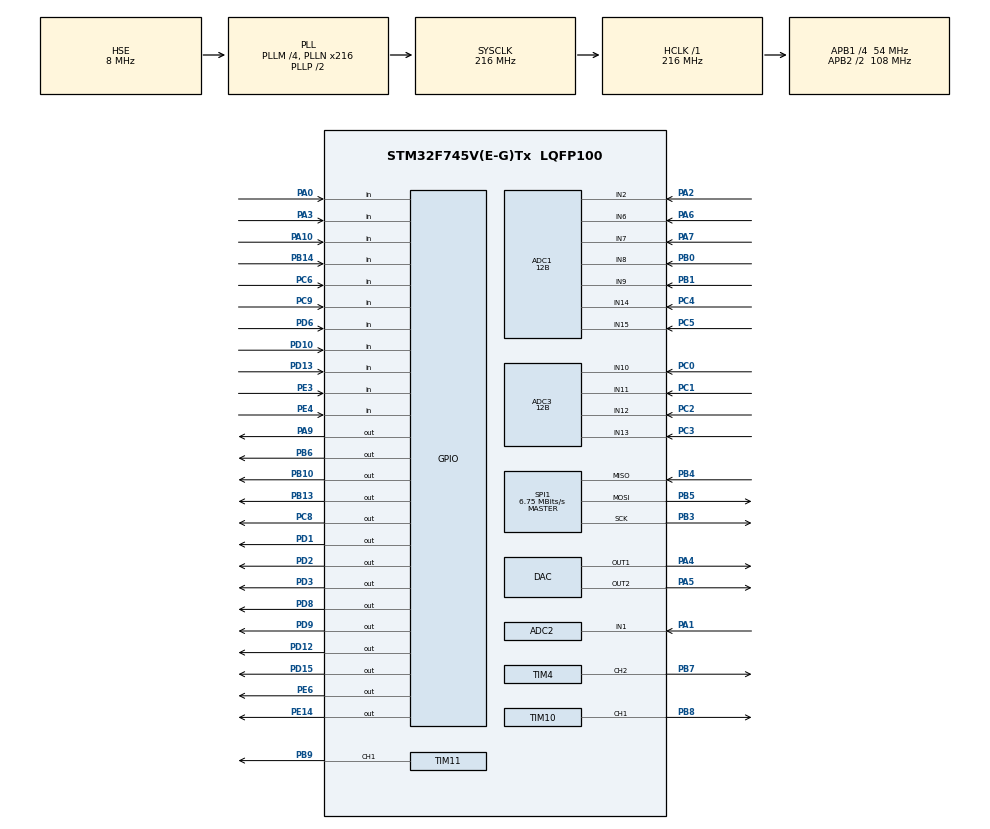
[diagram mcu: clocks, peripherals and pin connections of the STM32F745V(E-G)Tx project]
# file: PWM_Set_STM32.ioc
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ADC1.Channel-0\#ChannelRegularConversion=ADC_CHANNEL_2
ADC1.Channel-1\#ChannelRegularConversion=ADC_CHANNEL_6
ADC1.Channel-2\#ChannelRegularConversion=ADC_CHANNEL_7
ADC1.Channel-3\#ChannelRegularConversion=ADC_CHANNEL_14
ADC1.Channel-4\#ChannelRegularConversion=ADC_CHANNEL_15
ADC1.Channel-5\#ChannelRegularConversion=ADC_CHANNEL_8
ADC1.Channel-6\#ChannelRegularConversion=ADC_CHANNEL_9
ADC1.ClockPrescaler=ADC_CLOCK_SYNC_PCLK_DIV4
ADC1.ContinuousConvMode=ENABLE
ADC1.DMAContinuousRequests=ENABLE
ADC1.DataAlign=ADC_DATAALIGN_RIGHT
ADC1.DiscontinuousConvMode=DISABLE
ADC1.EOCSelection=ADC_EOC_SEQ_CONV
ADC1.EnableAnalogWatchDog=false
ADC1.ExternalTrigConv=ADC_SOFTWARE_START
ADC1.ExternalTrigConvEdge=ADC_EXTERNALTRIGCONVEDGE_NONE
ADC1.InjNumberOfConversion=0
ADC1.NbrOfConversion=7
ADC1.NbrOfConversionFlag=1
ADC1.Rank-0\#ChannelRegularConversion=1
ADC1.Rank-1\#ChannelRegularConversion=2
ADC1.Rank-2\#ChannelRegularConversion=3
ADC1.Rank-3\#ChannelRegularConversion=4
ADC1.Rank-4\#ChannelRegularConversion=5
ADC1.Rank-5\#ChannelRegularConversion=6
ADC1.Rank-6\#ChannelRegularConversion=7
ADC1.Resolution=ADC_RESOLUTION_12B
ADC1.SamplingTime-0\#ChannelRegularConversion=ADC_SAMPLETIME_3CYCLES
ADC1.SamplingTime-1\#ChannelRegularConversion=ADC_SAMPLETIME_3CYCLES
ADC1.SamplingTime-2\#ChannelRegularConversion=ADC_SAMPLETIME_3CYCLES
ADC1.SamplingTime-3\#ChannelRegularConversion=ADC_SAMPLETIME_3CYCLES
ADC1.SamplingTime-4\#ChannelRegularConversion=ADC_SAMPLETIME_3CYCLES
ADC1.SamplingTime-5\#ChannelRegularConversion=ADC_SAMPLETIME_3CYCLES
ADC1.SamplingTime-6\#ChannelRegularConversion=ADC_SAMPLETIME_3CYCLES
ADC1.ScanConvMode=ENABLE
ADC1.master=1
ADC2.Channel-0\#ChannelRegularConversion=ADC_CHANNEL_1
ADC2.ClockPrescaler=ADC_CLOCK_SYNC_PCLK_DIV4
ADC2.DMAContinuousRequests=ENABLE
ADC2.EOCSelection=ADC_EOC_SEQ_CONV
ADC2.ExternalTrigConv=ADC_EXTERNALTRIGCONV_T8_TRGO
ADC2.NbrOfConversionFlag=1
ADC2.Rank-0\#ChannelRegularConversion=1
ADC2.SamplingTime-0\#ChannelRegularConversion=ADC_SAMPLETIME_3CYCLES
ADC2.ScanConvMode=ENABLE
ADC3.Channel-0\#ChannelRegularConversion=ADC_CHANNEL_10
ADC3.Channel-1\#ChannelRegularConversion=ADC_CHANNEL_11
ADC3.Channel-2\#ChannelRegularConversion=ADC_CHANNEL_12
ADC3.Channel-3\#ChannelRegularConversion=ADC_CHANNEL_13
ADC3.ClockPrescaler=ADC_CLOCK_SYNC_PCLK_DIV4
ADC3.ContinuousConvMode=DISABLE
ADC3.DMAContinuousRequests=ENABLE
ADC3.DataAlign=ADC_DATAALIGN_RIGHT
ADC3.DiscontinuousConvMode=DISABLE
ADC3.EOCSelection=ADC_EOC_SEQ_CONV
ADC3.EnableAnalogWatchDog=false
ADC3.ExternalTrigConv=ADC_EXTERNALTRIGCONV_T6_TRGO
ADC3.ExternalTrigConvEdge=ADC_EXTERNALTRIGCONVEDGE_RISING
ADC3.InjNumberOfConversion=0
ADC3.NbrOfConversion=4
ADC3.NbrOfConversionFlag=1
ADC3.Rank-0\#ChannelRegularConversion=1
ADC3.Rank-1\#ChannelRegularConversion=2
ADC3.Rank-2\#ChannelRegularConversion=3
ADC3.Rank-3\#ChannelRegularConversion=4
ADC3.Resolution=ADC_RESOLUTION_12B
ADC3.SamplingTime-0\#ChannelRegularConversion=ADC_SAMPLETIME_3CYCLES
ADC3.SamplingTime-1\#ChannelRegularConversion=ADC_SAMPLETIME_3CYCLES
ADC3.SamplingTime-2\#ChannelRegularConversion=ADC_SAMPLETIME_3CYCLES
ADC3.SamplingTime-3\#ChannelRegularConversion=ADC_SAMPLETIME_3CYCLES
ADC3.ScanConvMode=ENABLE
Dma.ADC1.3.Direction=DMA_PERIPH_TO_MEMORY
Dma.ADC1.3.FIFOMode=DMA_FIFOMODE_DISABLE
Dma.ADC1.3.Instance=DMA2_Stream4
Dma.ADC1.3.MemDataAlignment=DMA_MDATAALIGN_HALFWORD
Dma.ADC1.3.MemInc=DMA_MINC_ENABLE
Dma.ADC1.3.Mode=DMA_CIRCULAR
Dma.ADC1.3.PeriphDataAlignment=DMA_PDATAALIGN_HALFWORD
Dma.ADC1.3.PeriphInc=DMA_PINC_DISABLE
Dma.ADC1.3.Priority=DMA_PRIORITY_LOW
Dma.ADC2.0.Direction=DMA_PERIPH_TO_MEMORY
Dma.ADC2.0.FIFOMode=DMA_FIFOMODE_DISABLE
Dma.ADC2.0.Instance=DMA2_Stream2
Dma.ADC2.0.MemDataAlignment=DMA_MDATAALIGN_HALFWORD
Dma.ADC2.0.MemInc=DMA_MINC_ENABLE
Dma.ADC2.0.Mode=DMA_NORMAL
Dma.ADC2.0.PeriphDataAlignment=DMA_PDATAALIGN_HALFWORD
Dma.ADC2.0.PeriphInc=DMA_PINC_DISABLE
Dma.ADC2.0.Priority=DMA_PRIORITY_LOW
Dma.ADC3.4.Direction=DMA_PERIPH_TO_MEMORY
Dma.ADC3.4.FIFOMode=DMA_FIFOMODE_DISABLE
Dma.ADC3.4.Instance=DMA2_Stream1
Dma.ADC3.4.MemDataAlignment=DMA_MDATAALIGN_HALFWORD
Dma.ADC3.4.MemInc=DMA_MINC_ENABLE
Dma.ADC3.4.Mode=DMA_NORMAL
Dma.ADC3.4.PeriphDataAlignment=DMA_PDATAALIGN_HALFWORD
Dma.ADC3.4.PeriphInc=DMA_PINC_DISABLE
Dma.ADC3.4.Priority=DMA_PRIORITY_LOW
Dma.Request0=ADC2
Dma.Request1=SPI1_RX
Dma.Request2=SPI1_TX
Dma.Request3=ADC1
Dma.Request4=ADC3
Dma.SPI1_RX.1.Direction=DMA_PERIPH_TO_MEMORY
Dma.SPI1_RX.1.FIFOMode=DMA_FIFOMODE_DISABLE
Dma.SPI1_RX.1.Instance=DMA2_Stream0
Dma.SPI1_RX.1.MemDataAlignment=DMA_MDATAALIGN_BYTE
Dma.SPI1_RX.1.MemInc=DMA_MINC_ENABLE
Dma.SPI1_RX.1.Mode=DMA_NORMAL
Dma.SPI1_RX.1.PeriphDataAlignment=DMA_PDATAALIGN_BYTE
Dma.SPI1_RX.1.PeriphInc=DMA_PINC_DISABLE
Dma.SPI1_RX.1.Priority=DMA_PRIORITY_LOW
Dma.SPI1_TX.2.Direction=DMA_MEMORY_TO_PERIPH
Dma.SPI1_TX.2.FIFOMode=DMA_FIFOMODE_DISABLE
Dma.SPI1_TX.2.Instance=DMA2_Stream3
Dma.SPI1_TX.2.MemDataAlignment=DMA_MDATAALIGN_BYTE
Dma.SPI1_TX.2.MemInc=DMA_MINC_ENABLE
Dma.SPI1_TX.2.Mode=DMA_NORMAL
Dma.SPI1_TX.2.PeriphDataAlignment=DMA_PDATAALIGN_BYTE
Dma.SPI1_TX.2.PeriphInc=DMA_PINC_DISABLE
Dma.SPI1_TX.2.Priority=DMA_PRIORITY_LOW
FREERTOS.Tasks01=defaultTask,0,128,StartDefaultTask,Default,NULL,Dynamic,NULL,NULL;statusTask,-3,128,StartStatusTask,Default,NULL,Dynamic,NULL,NULL
Mcu.Family=STM32F7
Mcu.Name=STM32F745V(E-G)Tx
Mcu.Package=LQFP100
NVIC.DMA2_Stream0_IRQn=true\:5\:0\:false\:false\:true\:true\:true
NVIC.DMA2_Stream1_IRQn=true\:5\:0\:false\:false\:true\:true\:true
NVIC.DMA2_Stream2_IRQn=true\:5\:0\:false\:false\:true\:true\:true
NVIC.DMA2_Stream3_IRQn=true\:5\:0\:false\:false\:true\:true\:true
NVIC.DMA2_Stream4_IRQn=true\:5\:0\:false\:false\:true\:true\:true
NVIC.PriorityGroup=NVIC_PRIORITYGROUP_4
NVIC.TIM2_IRQn=true\:0\:0\:false\:false\:true\:false\:true
NVIC.TimeBase=TIM2_IRQn
NVIC.TimeBaseIP=TIM2
PA0/WKUP.Signal=GPIO_Input
PA1.Signal=ADCx_IN1
PA10.Signal=GPIO_Input
PA13.Mode=Serial_Wire
PA13.Signal=SYS_JTMS-SWDIO
PA14.Mode=Serial_Wire
PA14.Signal=SYS_JTCK-SWCLK
PA2.Signal=ADCx_IN2
PA3.Signal=GPIO_Input
PA4.Signal=COMP_DAC1_group
PA5.Signal=COMP_DAC2_group
PA6.Signal=ADCx_IN6
PA7.Signal=ADCx_IN7
PA9.Signal=GPIO_Output
PB0.Signal=ADCx_IN8
PB1.Signal=ADCx_IN9
PB10.Signal=GPIO_Output
PB13.Signal=GPIO_Output
PB14.Signal=GPIO_Input
PB3.Mode=Full_Duplex_Master
PB3.Signal=SPI1_SCK
PB4.Mode=Full_Duplex_Master
PB4.Signal=SPI1_MISO
PB5.Mode=Full_Duplex_Master
PB5.Signal=SPI1_MOSI
PB6.Signal=GPIO_Output
PB7.Signal=S_TIM4_CH2
PB8.Signal=S_TIM10_CH1
PB9.Signal=S_TIM11_CH1
PC0.Signal=ADCx_IN10
PC1.Signal=ADCx_IN11
PC14/OSC32_IN.Mode=LSE-External-Oscillator
PC14/OSC32_IN.Signal=RCC_OSC32_IN
PC15/OSC32_OUT.Mode=LSE-External-Oscillator
PC15/OSC32_OUT.Signal=RCC_OSC32_OUT
PC2.Signal=ADCx_IN12
PC3.Signal=ADCx_IN13
PC4.Signal=ADCx_IN14
PC5.Signal=ADCx_IN15
PC6.Signal=GPIO_Input
PC8.Signal=GPIO_Output
PC9.Signal=GPIO_Input
PD1.Signal=GPIO_Output
PD10.Signal=GPIO_Input
PD12.Signal=GPIO_Output
PD13.Signal=GPIO_Input
PD15.Signal=GPIO_Output
PD2.Signal=GPIO_Output
PD3.Signal=GPIO_Output
PD6.Signal=GPIO_Input
PD8.Signal=GPIO_Output
PD9.Signal=GPIO_Output
PE14.Signal=GPIO_Output
PE3.Signal=GPIO_Input
PE4.Signal=GPIO_Input
PE6.Signal=GPIO_Output
PH0/OSC_IN.Mode=HSE-External-Oscillator
PH0/OSC_IN.Signal=RCC_OSC_IN
PH1/OSC_OUT.Mode=HSE-External-Oscillator
PH1/OSC_OUT.Signal=RCC_OSC_OUT
ProjectManager.HeapSize=0x200
ProjectManager.StackSize=0x400
ProjectManager.TargetToolchain=MDK-ARM V5
RCC.AHBFreq_Value=216000000
RCC.APB1CLKDivider=RCC_HCLK_DIV4
RCC.APB1Freq_Value=54000000
RCC.APB1TimFreq_Value=108000000
RCC.APB2CLKDivider=RCC_HCLK_DIV2
RCC.APB2Freq_Value=108000000
RCC.APB2TimFreq_Value=216000000
RCC.CortexFreq_Value=216000000
RCC.HCLKFreq_Value=216000000
RCC.HSE_VALUE=8000000
RCC.HSI_VALUE=16000000
RCC.PLLM=4
RCC.PLLN=216
RCC.PLLSourceVirtual=RCC_PLLSOURCE_HSE
RCC.SYSCLKFreq_VALUE=216000000
RCC.SYSCLKSource=RCC_SYSCLKSOURCE_PLLCLK
RCC.USBFreq_Value=216000000
RCC.VCOOutputFreq_Value=432000000
SH.ADCx_IN1.0=ADC2_IN1,IN1
SH.ADCx_IN10.0=ADC3_IN10,IN10
SH.ADCx_IN11.0=ADC3_IN11,IN11
SH.ADCx_IN12.0=ADC3_IN12,IN12
SH.ADCx_IN13.0=ADC3_IN13,IN13
SH.ADCx_IN14.0=ADC1_IN14,IN14
SH.ADCx_IN15.0=ADC1_IN15,IN15
SH.ADCx_IN2.0=ADC1_IN2,IN2
SH.ADCx_IN6.0=ADC1_IN6,IN6
SH.ADCx_IN7.0=ADC1_IN7,IN7
SH.ADCx_IN8.0=ADC1_IN8,IN8
SH.ADCx_IN9.0=ADC1_IN9,IN9
SH.COMP_DAC1_group.0=DAC_OUT1,DAC_OUT1
SH.COMP_DAC2_group.0=DAC_OUT2,DAC_OUT2
SH.S_TIM10_CH1.0=TIM10_CH1,PWM Generation1 CH1
SH.S_TIM11_CH1.0=TIM11_CH1,PWM Generation1 CH1
SH.S_TIM4_CH2.0=TIM4_CH2,PWM Generation2 CH2
SPI1.BaudRatePrescaler=SPI_BAUDRATEPRESCALER_16
SPI1.CalculateBaudRate=6.75 MBits/s
SPI1.DataSize=SPI_DATASIZE_8BIT
SPI1.Direction=SPI_DIRECTION_2LINES
SPI1.Mode=SPI_MODE_MASTER
SPI1.NSSPMode=SPI_NSS_PULSE_DISABLE
SPI1.VirtualType=VM_MASTER
TIM10.Channel=TIM_CHANNEL_1
TIM10.Period=1024
TIM11.Channel=TIM_CHANNEL_1
TIM11.Period=1024
TIM4.Channel-PWM\ Generation2\ CH2=TIM_CHANNEL_2
TIM4.Period=1024
TIM6.Period=216
TIM6.TIM_MasterOutputTrigger=TIM_TRGO_UPDATE
TIM8.Period=216
TIM8.TIM_MasterOutputTrigger=TIM_TRGO_UPDATE
TIM8.TIM_MasterOutputTrigger2=TIM_TRGO2_UPDATE
VP_FREERTOS_VS_ENABLE.Mode=Enabled
VP_SYS_VS_tim2.Mode=TIM2
VP_TIM10_VS_ClockSourceINT.Mode=Enable_Timer
VP_TIM11_VS_ClockSourceINT.Mode=Enable_Timer
VP_TIM6_VS_ClockSourceINT.Mode=Enable_Timer
VP_TIM8_VS_ClockSourceINT.Mode=Internal
board=PWM_Set_STM32

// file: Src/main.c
/**
  ******************************************************************************
  * @file           : main.c
  * @brief          : Main program body
  ******************************************************************************
  * This notice applies to any and all portions of this file
  * that are not between comment pairs USER CODE BEGIN and
  * USER CODE END. Other portions of this file, whether
  * inserted by the user or by software development tools
  * are owned by their respective copyright owners.
  *
  * Copyright (c) 2018 STMicroelectronics International N.V.
  * All rights reserved.
  *
  * Redistribution and use in source and binary forms, with or without
  * modification, are permitted, provided that the following conditions are met:
  *
  * 1. Redistribution of source code must retain the above copyright notice,
  *    this list of conditions and the following disclaimer.
  * 2. Redistributions in binary form must reproduce the above copyright notice,
  *    this list of conditions and the following disclaimer in the documentation
  *    and/or other materials provided with the distribution.
  * 3. Neither the name of STMicroelectronics nor the names of other
  *    contributors to this software may be used to endorse or promote products
  *    derived from this software without specific written permission.
  * 4. This software, including modifications and/or derivative works of this
  *    software, must execute solely and exclusively on microcontroller or
  *    microprocessor devices manufactured by or for STMicroelectronics.
  * 5. Redistribution and use of this software other than as permitted under
  *    this license is void and will automatically terminate your rights under
  *    this license.
  *
  * THIS SOFTWARE IS PROVIDED BY STMICROELECTRONICS AND CONTRIBUTORS "AS IS"
  * AND ANY EXPRESS, IMPLIED OR STATUTORY WARRANTIES, INCLUDING, BUT NOT
  * LIMITED TO, THE IMPLIED WARRANTIES OF MERCHANTABILITY, FITNESS FOR A
  * PARTICULAR PURPOSE AND NON-INFRINGEMENT OF THIRD PARTY INTELLECTUAL PROPERTY
  * RIGHTS ARE DISCLAIMED TO THE FULLEST EXTENT PERMITTED BY LAW. IN NO EVENT
  * SHALL STMICROELECTRONICS OR CONTRIBUTORS BE LIABLE FOR ANY DIRECT, INDIRECT,
  * INCIDENTAL, SPECIAL, EXEMPLARY, OR CONSEQUENTIAL DAMAGES (INCLUDING, BUT NOT
  * LIMITED TO, PROCUREMENT OF SUBSTITUTE GOODS OR SERVICES; LOSS OF USE, DATA,
  * OR PROFITS; OR BUSINESS INTERRUPTION) HOWEVER CAUSED AND ON ANY THEORY OF
  * LIABILITY, WHETHER IN CONTRACT, STRICT LIABILITY, OR TORT (INCLUDING
  * NEGLIGENCE OR OTHERWISE) ARISING IN ANY WAY OUT OF THE USE OF THIS SOFTWARE,
  * EVEN IF ADVISED OF THE POSSIBILITY OF SUCH DAMAGE.
  *
  ******************************************************************************
  */
#include "main.h"
#include "stm32f7xx_hal.h"
#include "cmsis_os.h"
#include "adc.h"
#include "dac.h"
#include "dma.h"
#include "spi.h"
#include "tim.h"
#include "gpio.h"

/* USER CODE BEGIN PV */
/* Private variables ---------------------------------------------------------*/

/* USER CODE END PV */

void SystemClock_Config(void);
void MX_FREERTOS_Init(void);

/* USER CODE BEGIN PFP */
/* Private function prototypes -----------------------------------------------*/

/* USER CODE END PFP */

int main(void)
{

  /* MCU Configuration----------------------------------------------------------*/

  /* Reset of all peripherals, Initializes the Flash interface and the Systick. */
  HAL_Init();

  /* Configure the system clock */
  SystemClock_Config();

  /* Initialize all configured peripherals */
  MX_GPIO_Init();
  MX_DMA_Init();
  MX_ADC1_Init();
  MX_ADC2_Init();
  MX_ADC3_Init();
  MX_DAC_Init();
  MX_SPI1_Init();
  MX_TIM4_Init();
  MX_TIM6_Init();
  MX_TIM8_Init();
  MX_TIM10_Init();
  MX_TIM11_Init();

  /* Call init function for freertos objects (in freertos.c) */
  MX_FREERTOS_Init();

  /* Start scheduler */
  osKernelStart();

  /* We should never get here as control is now taken by the scheduler */

  /* Infinite loop */
  while (1)
  {

  }

}

void SystemClock_Config(void)
{

  RCC_OscInitTypeDef RCC_OscInitStruct;
  RCC_ClkInitTypeDef RCC_ClkInitStruct;

    /**Configure the main internal regulator output voltage
    */
  __HAL_RCC_PWR_CLK_ENABLE();

  __HAL_PWR_VOLTAGESCALING_CONFIG(PWR_REGULATOR_VOLTAGE_SCALE1);

    /**Initializes the CPU, AHB and APB busses clocks
    */
  RCC_OscInitStruct.OscillatorType = RCC_OSCILLATORTYPE_HSE;
  RCC_OscInitStruct.HSEState = RCC_HSE_ON;
  RCC_OscInitStruct.PLL.PLLState = RCC_PLL_ON;
  RCC_OscInitStruct.PLL.PLLSource = RCC_PLLSOURCE_HSE;
  RCC_OscInitStruct.PLL.PLLM = 4;
  RCC_OscInitStruct.PLL.PLLN = 216;
  RCC_OscInitStruct.PLL.PLLP = RCC_PLLP_DIV2;
  RCC_OscInitStruct.PLL.PLLQ = 2;
  if (HAL_RCC_OscConfig(&RCC_OscInitStruct) != HAL_OK)
  {
    _Error_Handler(__FILE__, __LINE__);
  }

    /**Activate the Over-Drive mode
    */
  if (HAL_PWREx_EnableOverDrive() != HAL_OK)
  {
    _Error_Handler(__FILE__, __LINE__);
  }

    /**Initializes the CPU, AHB and APB busses clocks
    */
  RCC_ClkInitStruct.ClockType = RCC_CLOCKTYPE_HCLK|RCC_CLOCKTYPE_SYSCLK
                              |RCC_CLOCKTYPE_PCLK1|RCC_CLOCKTYPE_PCLK2;
  RCC_ClkInitStruct.SYSCLKSource = RCC_SYSCLKSOURCE_PLLCLK;
  RCC_ClkInitStruct.AHBCLKDivider = RCC_SYSCLK_DIV1;
  RCC_ClkInitStruct.APB1CLKDivider = RCC_HCLK_DIV4;
  RCC_ClkInitStruct.APB2CLKDivider = RCC_HCLK_DIV2;

  if (HAL_RCC_ClockConfig(&RCC_ClkInitStruct, FLASH_LATENCY_7) != HAL_OK)
  {
    _Error_Handler(__FILE__, __LINE__);
  }

    /**Configure the Systick interrupt time
    */
  HAL_SYSTICK_Config(HAL_RCC_GetHCLKFreq()/1000);

    /**Configure the Systick
    */
  HAL_SYSTICK_CLKSourceConfig(SYSTICK_CLKSOURCE_HCLK);

  /* SysTick_IRQn interrupt configuration */
  HAL_NVIC_SetPriority(SysTick_IRQn, 15, 0);
}

void HAL_TIM_PeriodElapsedCallback(TIM_HandleTypeDef *htim)
{
  if (htim->Instance == TIM2) {
    HAL_IncTick();
  }
}

void _Error_Handler(char *file, int line)
{
  while(1)
  {
  }
}

/************************ (C) COPYRIGHT STMicroelectronics *****END OF FILE****/

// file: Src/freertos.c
/**
  ******************************************************************************
  * File Name          : freertos.c
  * Description        : Code for freertos applications
  ******************************************************************************
  * This notice applies to any and all portions of this file
  * that are not between comment pairs USER CODE BEGIN and
  * USER CODE END. Other portions of this file, whether
  * inserted by the user or by software development tools
  * are owned by their respective copyright owners.
  *
  * Copyright (c) 2018 STMicroelectronics International N.V.
  * All rights reserved.
  *
  * Redistribution and use in source and binary forms, with or without
  * modification, are permitted, provided that the following conditions are met:
  *
  * 1. Redistribution of source code must retain the above copyright notice,
  *    this list of conditions and the following disclaimer.
  * 2. Redistributions in binary form must reproduce the above copyright notice,
  *    this list of conditions and the following disclaimer in the documentation
  *    and/or other materials provided with the distribution.
  * 3. Neither the name of STMicroelectronics nor the names of other
  *    contributors to this software may be used to endorse or promote products
  *    derived from this software without specific written permission.
  * 4. This software, including modifications and/or derivative works of this
  *    software, must execute solely and exclusively on microcontroller or
  *    microprocessor devices manufactured by or for STMicroelectronics.
  * 5. Redistribution and use of this software other than as permitted under
  *    this license is void and will automatically terminate your rights under
  *    this license.
  *
  * THIS SOFTWARE IS PROVIDED BY STMICROELECTRONICS AND CONTRIBUTORS "AS IS"
  * AND ANY EXPRESS, IMPLIED OR STATUTORY WARRANTIES, INCLUDING, BUT NOT
  * LIMITED TO, THE IMPLIED WARRANTIES OF MERCHANTABILITY, FITNESS FOR A
  * PARTICULAR PURPOSE AND NON-INFRINGEMENT OF THIRD PARTY INTELLECTUAL PROPERTY
  * RIGHTS ARE DISCLAIMED TO THE FULLEST EXTENT PERMITTED BY LAW. IN NO EVENT
  * SHALL STMICROELECTRONICS OR CONTRIBUTORS BE LIABLE FOR ANY DIRECT, INDIRECT,
  * INCIDENTAL, SPECIAL, EXEMPLARY, OR CONSEQUENTIAL DAMAGES (INCLUDING, BUT NOT
  * LIMITED TO, PROCUREMENT OF SUBSTITUTE GOODS OR SERVICES; LOSS OF USE, DATA,
  * OR PROFITS; OR BUSINESS INTERRUPTION) HOWEVER CAUSED AND ON ANY THEORY OF
  * LIABILITY, WHETHER IN CONTRACT, STRICT LIABILITY, OR TORT (INCLUDING
  * NEGLIGENCE OR OTHERWISE) ARISING IN ANY WAY OUT OF THE USE OF THIS SOFTWARE,
  * EVEN IF ADVISED OF THE POSSIBILITY OF SUCH DAMAGE.
  *
  ******************************************************************************
  */

#include "FreeRTOS.h"
#include "task.h"
#include "cmsis_os.h"

osThreadId defaultTaskHandle;
osThreadId statusTaskHandle;

void StartDefaultTask(void const * argument);
void StartStatusTask(void const * argument);

void MX_FREERTOS_Init(void); /* (MISRA C 2004 rule 8.1) */

/* USER CODE BEGIN FunctionPrototypes */
extern void USER_MAIN_StartupInit(void);
extern void USER_MAIN_CalculateValues(void);
extern void USER_MAIN_ENC26J60_CheckPackets(void);
/* USER CODE END FunctionPrototypes */

/* Hook prototypes */

/* Init FreeRTOS */

void MX_FREERTOS_Init(void) {

  /* Create the thread(s) */
  /* definition and creation of defaultTask */
  osThreadDef(defaultTask, StartDefaultTask, osPriorityNormal, 0, 128);
  defaultTaskHandle = osThreadCreate(osThread(defaultTask), NULL);

  /* definition and creation of statusTask */
  osThreadDef(statusTask, StartStatusTask, osPriorityIdle, 0, 128);
  statusTaskHandle = osThreadCreate(osThread(statusTask), NULL);

}

/* StartDefaultTask function */
void StartDefaultTask(void const * argument)
{

  /* USER CODE BEGIN StartDefaultTask */
	osDelay(250);
	USER_MAIN_StartupInit();
  /* Infinite loop */
  for(;;)
  {
		USER_MAIN_ENC26J60_CheckPackets();
    osDelay(1);
  }
  /* USER CODE END StartDefaultTask */
}

/* StartStatusTask function */
void StartStatusTask(void const * argument)
{
  /* USER CODE BEGIN StartStatusTask */
  /* Infinite loop */
  for(;;)
  {
		USER_MAIN_CalculateValues();
    osDelay(250);
  }
  /* USER CODE END StartStatusTask */
}

/************************ (C) COPYRIGHT STMicroelectronics *****END OF FILE****/
